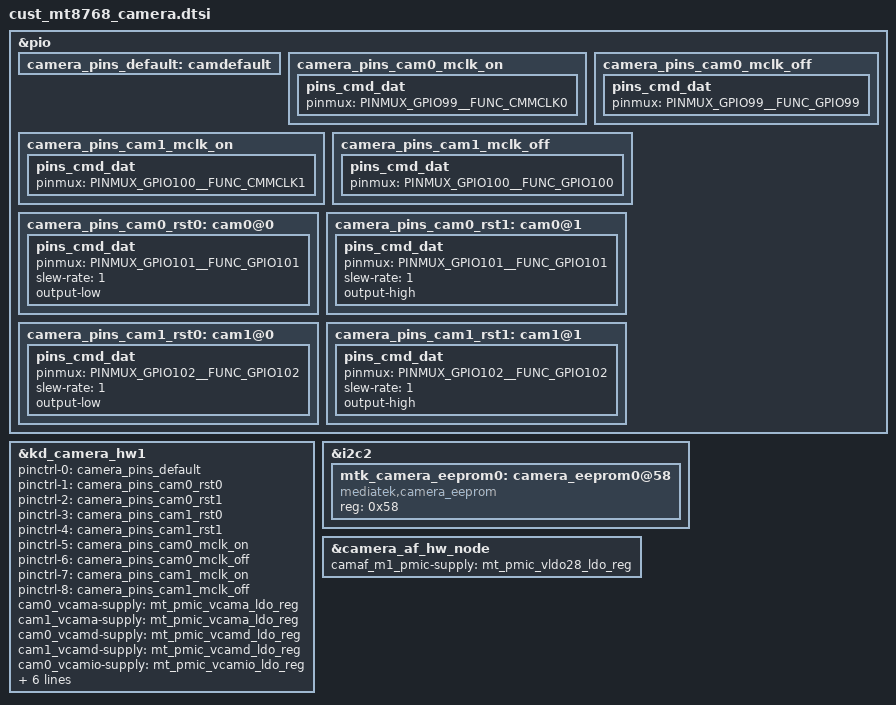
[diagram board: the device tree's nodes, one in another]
// SPDX-License-Identifier: GPL-2.0+
/*
 * Copyright (c) 2019 MediaTek Inc.
 *
 */

/* CAMERA GPIO standardization */
&pio {
	camera_pins_default: camdefault {
	};

	camera_pins_cam0_mclk_on: camera_pins_cam0_mclk_on {
		pins_cmd_dat {
			pinmux = <PINMUX_GPIO99__FUNC_CMMCLK0>;
		};
	};

	camera_pins_cam0_mclk_off: camera_pins_cam0_mclk_off {
		pins_cmd_dat {
			pinmux = <PINMUX_GPIO99__FUNC_GPIO99>;
		};
	};

	camera_pins_cam1_mclk_on: camera_pins_cam1_mclk_on {
		pins_cmd_dat {
			pinmux = <PINMUX_GPIO100__FUNC_CMMCLK1>;
		};
	};

	camera_pins_cam1_mclk_off: camera_pins_cam1_mclk_off {
		pins_cmd_dat {
			pinmux = <PINMUX_GPIO100__FUNC_GPIO100>;
		};
	};

	camera_pins_cam0_rst0: cam0@0 {
		pins_cmd_dat {
			pinmux = <PINMUX_GPIO101__FUNC_GPIO101>;
			slew-rate = <1>;
			output-low;
		};
	};

	camera_pins_cam0_rst1: cam0@1 {
		pins_cmd_dat {
			pinmux = <PINMUX_GPIO101__FUNC_GPIO101>;
			slew-rate = <1>;
			output-high;
		};
	};


	camera_pins_cam1_rst0: cam1@0 {
		pins_cmd_dat {
			pinmux = <PINMUX_GPIO102__FUNC_GPIO102>;
			slew-rate = <1>;
			output-low;
		};
	};

	camera_pins_cam1_rst1: cam1@1 {
		pins_cmd_dat {
			pinmux = <PINMUX_GPIO102__FUNC_GPIO102>;
			slew-rate = <1>;
			output-high;
		};
	};

};

&kd_camera_hw1 {
	pinctrl-names = "default",
			"cam0_rst0",
			"cam0_rst1",
			"cam1_rst0",
			"cam1_rst1",
			"cam0_mclk_on",
			"cam0_mclk_off",
			"cam1_mclk_on",
			"cam1_mclk_off";


	pinctrl-0 = <&camera_pins_default>;
	pinctrl-1 = <&camera_pins_cam0_rst0>;
	pinctrl-2 = <&camera_pins_cam0_rst1>;
	pinctrl-3 = <&camera_pins_cam1_rst0>;
	pinctrl-4 = <&camera_pins_cam1_rst1>;
	pinctrl-5 = <&camera_pins_cam0_mclk_on>;
	pinctrl-6 = <&camera_pins_cam0_mclk_off>;
	pinctrl-7 = <&camera_pins_cam1_mclk_on>;
	pinctrl-8 = <&camera_pins_cam1_mclk_off>;

	cam0_vcama-supply = <&mt_pmic_vcama_ldo_reg>;
	cam1_vcama-supply = <&mt_pmic_vcama_ldo_reg>;
	cam0_vcamd-supply = <&mt_pmic_vcamd_ldo_reg>;
	cam1_vcamd-supply = <&mt_pmic_vcamd_ldo_reg>;
	cam0_vcamio-supply = <&mt_pmic_vcamio_ldo_reg>;
	cam1_vcamio-supply = <&mt_pmic_vcamio_ldo_reg>;
	camaf_m1_pmic-supply = <&mt_pmic_vldo28_ldo_reg>;
	//vcamaf-supply = <&mt_pmic_vldo28_ldo_reg>;
	//vcamaf_sub-supply = <&mt_pmic_vldo28_ldo_reg>;
	status = "okay";

	cam0_enable_sensor = "s5k4h7yx_mipi_raw s5k4h7yxqtech_mipi_raw";
	cam1_enable_sensor = "gc5035kingcome_mipi_raw s5k5e9yx_mipi_raw ov5675_mipi_raw";
};

&i2c2 {
	mtk_camera_eeprom0:camera_eeprom0@58 {
		compatible = "mediatek,camera_eeprom";
		reg = <0x58>;
		status = "okay";
	};
};

&camera_af_hw_node {
	camaf_m1_pmic-supply = <&mt_pmic_vldo28_ldo_reg>;
	status = "okay";

};

/* CAMERA GPIO end */
